VERSION "created by canmatrix"

NS_ :

BS_:

BU_:

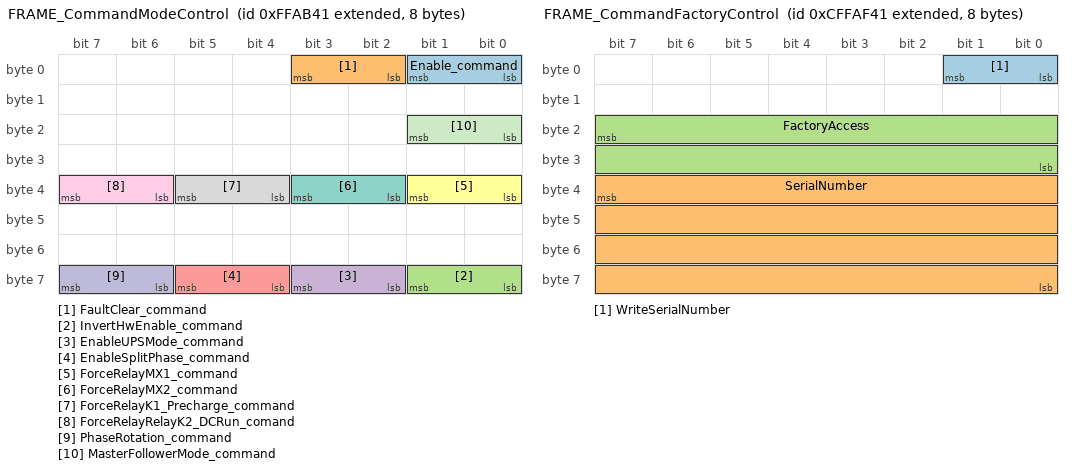
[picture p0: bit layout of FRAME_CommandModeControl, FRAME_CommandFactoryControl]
BO_ 2164239169 FRAME_CommandModeControl: 8 Vector__XXX
 SG_ Enable_command : 1|2@0- (1,0) [-2|1] "" Vector__XXX
 SG_ FaultClear_command : 3|2@0- (1,0) [-2|1] "" Vector__XXX
 SG_ InvertHwEnable_command : 57|2@0- (1,0) [-2|1] "" Vector__XXX
 SG_ EnableUPSMode_command : 59|2@0- (1,0) [-2|1] "" Vector__XXX
 SG_ EnableSplitPhase_command : 61|2@0- (1,0) [-2|1] "" Vector__XXX
 SG_ ForceRelayMX1_command : 33|2@0- (1,0) [-2|1] "" Vector__XXX
 SG_ ForceRelayMX2_command : 35|2@0- (1,0) [-2|1] "" Vector__XXX
 SG_ ForceRelayK1_Precharge_command : 37|2@0- (1,0) [-2|1] "" Vector__XXX
 SG_ ForceRelayRelayK2_DCRun_comand : 39|2@0- (1,0) [-2|1] "" Vector__XXX
 SG_ PhaseRotation_command : 63|2@0- (1,0) [-2|1] "" Vector__XXX
 SG_ MasterFollowerMode_command : 17|2@0- (1,0) [-2|1] "" Vector__XXX

BO_ 2365566017 FRAME_CommandPower: 8 Vector__XXX
 SG_ RealPower_command : 7|32@0- (1,0) [-2147483648|2147483647] "" Vector__XXX
 SG_ ReactivePower_command : 39|32@0- (1,0) [-2147483648|2147483647] "" Vector__XXX

BO_ 2365566529 FRAME_CommandVF: 8 Vector__XXX
 SG_ Voltage_command : 7|16@0- (0.1,0) [-3276.8|3276.7000000000003] "" Vector__XXX
 SG_ Frequency_command : 23|16@0- (0.1,0) [-3276.8|3276.7000000000003] "" Vector__XXX

BO_ 2365573878 FRAME_MasterMeasuredPower: 8 Vector__XXX
 SG_ RealPower_measured : 7|32@0- (1,0) [-2147483648|2147483647] "" Vector__XXX
 SG_ ReactivePower_measured : 39|32@0- (1,0) [-2147483648|2147483647] "" Vector__XXX

BO_ 2365566785 FRAME_CommandFactoryControl: 8 Vector__XXX
 SG_ WriteSerialNumber : 1|2@0- (1,0) [-2|1] "" Vector__XXX
 SG_ SerialNumber : 39|32@0- (1,0) [-2147483648|2147483647] "" Vector__XXX
 SG_ FactoryAccess : 23|16@0- (1,0) [-32768|32767] "" Vector__XXX

BO_ 2365565505 FRAME_CommandSetNVParam: 8 Vector__XXX
 SG_ CommandSetNVParam_MUX : 7|16@0- (1,0) [-32768|32767] "" Vector__XXX
 SG_ Dummy : 23|16@0- (1,0) [-32768|32767] "" Vector__XXX
 SG_ VUnder50pct : 23|16@0- (1,0) [-32768|32767] "" Vector__XXX
 SG_ V50to88pct : 39|16@0- (1,0) [-32768|32767] "" Vector__XXX
 SG_ V110to120pct : 55|16@0- (1,0) [-32768|32767] "" Vector__XXX
 SG_ VOver120 : 23|16@0- (1,0) [-32768|32767] "" Vector__XXX
 SG_ FreqHi0 : 23|16@0- (0.1,0) [-3276.8|3276.7000000000003] "" Vector__XXX
 SG_ FreqLo0 : 39|16@0- (0.1,0) [-3276.8|3276.7000000000003] "" Vector__XXX
 SG_ FreqVeryLo0 : 55|16@0- (0.1,0) [-3276.8|3276.7000000000003] "" Vector__XXX
 SG_ FreqVeryLo1 : 23|16@0- (0.1,0) [-3276.8|3276.7000000000003] "" Vector__XXX
 SG_ FreqLo1 : 39|16@0- (0.1,0) [-3276.8|3276.7000000000003] "" Vector__XXX
 SG_ FreqHi1 : 55|16@0- (0.1,0) [-3276.8|3276.7000000000003] "" Vector__XXX
 SG_ NodeID : 23|8@0- (1,0) [-128|127] "" Vector__XXX
 SG_ SA_Mask : 31|8@0- (1,0) [-128|127] "" Vector__XXX
 SG_ Baudrate : 39|4@0- (1,0) [-8|7] "" Vector__XXX
 SG_ ThermalOverload : 17|2@0- (1,0) [-2|1] "" Vector__XXX
 SG_ MX1Open : 23|16@0- (1,0) [-32768|32767] "" Vector__XXX
 SG_ MX1Close : 39|16@0- (1,0) [-32768|32767] "" Vector__XXX
 SG_ MX2Open : 55|16@0- (1,0) [-32768|32767] "" Vector__XXX
 SG_ MX2Close : 23|16@0- (1,0) [-32768|32767] "" Vector__XXX
 SG_ K1Open : 39|16@0- (1,0) [-32768|32767] "" Vector__XXX
 SG_ K1Close : 55|16@0- (1,0) [-32768|32767] "" Vector__XXX
 SG_ K2Open : 23|16@0- (1,0) [-32768|32767] "" Vector__XXX
 SG_ K2Close : 39|16@0- (1,0) [-32768|32767] "" Vector__XXX

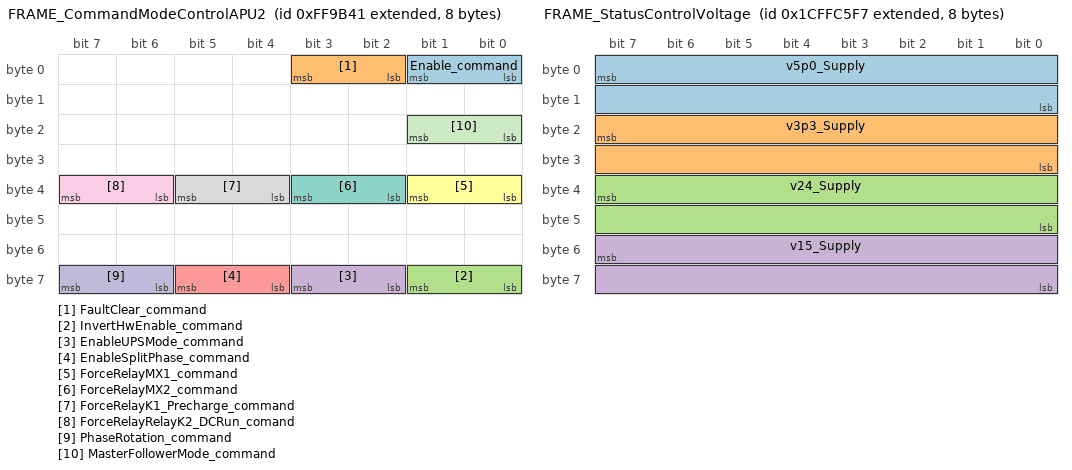
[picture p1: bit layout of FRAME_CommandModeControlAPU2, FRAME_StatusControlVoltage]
BO_ 2164235073 FRAME_CommandModeControlAPU2: 8 Vector__XXX
 SG_ Enable_command : 1|2@0- (1,0) [-2|1] "" Vector__XXX
 SG_ FaultClear_command : 3|2@0- (1,0) [-2|1] "" Vector__XXX
 SG_ InvertHwEnable_command : 57|2@0- (1,0) [-2|1] "" Vector__XXX
 SG_ EnableUPSMode_command : 59|2@0- (1,0) [-2|1] "" Vector__XXX
 SG_ EnableSplitPhase_command : 61|2@0- (1,0) [-2|1] "" Vector__XXX
 SG_ ForceRelayMX1_command : 33|2@0- (1,0) [-2|1] "" Vector__XXX
 SG_ ForceRelayMX2_command : 35|2@0- (1,0) [-2|1] "" Vector__XXX
 SG_ ForceRelayK1_Precharge_command : 37|2@0- (1,0) [-2|1] "" Vector__XXX
 SG_ ForceRelayRelayK2_DCRun_comand : 39|2@0- (1,0) [-2|1] "" Vector__XXX
 SG_ PhaseRotation_command : 63|2@0- (1,0) [-2|1] "" Vector__XXX
 SG_ MasterFollowerMode_command : 17|2@0- (1,0) [-2|1] "" Vector__XXX

BO_ 2365561921 FRAME_CommandPowerAPU2: 8 Vector__XXX
 SG_ RealPower_command : 7|32@0- (1,0) [-2147483648|2147483647] "" Vector__XXX
 SG_ ReactivePower_command : 39|32@0- (1,0) [-2147483648|2147483647] "" Vector__XXX

BO_ 2365562433 FRAME_CommandVFAPU2: 8 Vector__XXX
 SG_ Voltage_command : 7|16@0- (0.1,0) [-3276.8|3276.7000000000003] "" Vector__XXX
 SG_ Frequency_command : 23|16@0- (0.1,0) [-3276.8|3276.7000000000003] "" Vector__XXX

BO_ 2365573879 FRAME_MasterMeasuredPowerAPU2: 8 Vector__XXX
 SG_ RealPower_measured : 7|32@0- (1,0) [-2147483648|2147483647] "" Vector__XXX
 SG_ ReactivePower_measured : 39|32@0- (1,0) [-2147483648|2147483647] "" Vector__XXX

BO_ 2634001600 FRAME_justString: 8 Vector__XXX

BO_ 2634001344 FRAME_stringAndOther: 8 Vector__XXX
 SG_ RealPower_measured : 7|32@0- (1,0) [-2147483648|2147483647] "" Vector__XXX

BO_ 2365573879 FRAME_StatusMeasuredPower: 8 Vector__XXX
 SG_ RealPower_measured : 7|32@0- (1,0) [-2147483648|2147483647] "" Vector__XXX
 SG_ ReactivePower_measured : 39|32@0- (1,0) [-2147483648|2147483647] "" Vector__XXX

BO_ 2566898935 FRAME_StatusCommandedPower: 8 Vector__XXX
 SG_ RealPower_echo : 7|32@0- (1,0) [-2147483648|2147483647] "" Vector__XXX
 SG_ ReactivePower_echo : 39|32@0- (1,0) [-2147483648|2147483647] "" Vector__XXX

BO_ 2365572087 FRAME_StatusBits: 8 Vector__XXX
 SG_ State_status : 3|4@0- (1,0) [-8|7] "" Vector__XXX
 SG_ MX2Permissive_status : 19|2@0- (1,0) [-2|1] "" Vector__XXX
 SG_ PowerAvailAC_status : 11|2@0- (1,0) [-2|1] "" Vector__XXX
 SG_ PowerAvailDC_status : 13|2@0- (1,0) [-2|1] "" Vector__XXX
 SG_ PowerCircuitEnabled_status : 15|2@0- (1,0) [-2|1] "" Vector__XXX
 SG_ HardwareEnable_status : 9|2@0- (1,0) [-2|1] "" Vector__XXX
 SG_ Enable_echo : 5|2@0- (1,0) [-2|1] "" Vector__XXX
 SG_ FaultClr_echo : 7|2@0- (1,0) [-2|1] "" Vector__XXX
 SG_ MessageValidModeControl_status : 25|2@0- (1,0) [-2|1] "" Vector__XXX
 SG_ MX1Permissive_status : 17|2@0- (1,0) [-2|1] "" Vector__XXX
 SG_ K2DCRunPermissive_status : 23|2@0- (1,0) [-2|1] "" Vector__XXX
 SG_ K1PrechargePermissive_status : 21|2@0- (1,0) [-2|1] "" Vector__XXX
 SG_ MessageValidPowerCMD_status : 27|2@0- (1,0) [-2|1] "" Vector__XXX
 SG_ MessageValidVF_status : 29|2@0- (1,0) [-2|1] "" Vector__XXX
 SG_ CANbus_status : 31|2@0- (1,0) [-2|1] "" Vector__XXX
 SG_ EnableUPSMode_echo : 33|2@0- (1,0) [-2|1] "" Vector__XXX
 SG_ EnableSplitPhase_echo : 35|2@0- (1,0) [-2|1] "" Vector__XXX
 SG_ PhaseRotation_status : 37|2@0- (1,0) [-2|1] "" Vector__XXX
 SG_ LineVoltageDetected_status : 39|2@0- (1,0) [-2|1] "" Vector__XXX
 SG_ PhaseRotation_echo : 41|2@0- (1,0) [-2|1] "" Vector__XXX

BO_ 2634008055 FRAME_StatusControlVoltage: 8 Vector__XXX
 SG_ v5p0_Supply : 7|16@0- (0.01,0) [-327.68|327.67] "" Vector__XXX
 SG_ v3p3_Supply : 23|16@0- (0.01,0) [-327.68|327.67] "" Vector__XXX
 SG_ v24_Supply : 39|16@0- (0.01,0) [-327.68|327.67] "" Vector__XXX
 SG_ v15_Supply : 55|16@0- (0.01,0) [-327.68|327.67] "" Vector__XXX

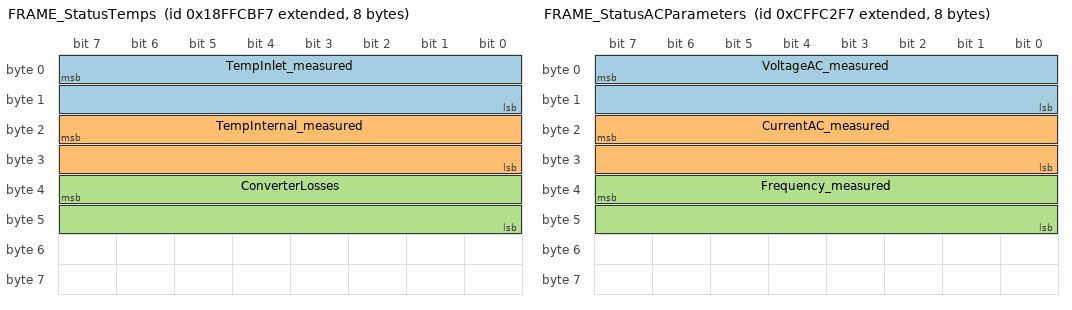
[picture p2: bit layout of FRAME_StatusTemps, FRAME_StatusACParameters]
BO_ 2566900727 FRAME_StatusTemps: 8 Vector__XXX
 SG_ TempInlet_measured : 7|16@0- (0.1,0) [-3276.8|3276.7000000000003] "" Vector__XXX
 SG_ TempInternal_measured : 23|16@0- (0.1,0) [-3276.8|3276.7000000000003] "" Vector__XXX
 SG_ ConverterLosses : 39|16@0- (1,0) [-32768|32767] "" Vector__XXX

BO_ 2365573367 FRAME_StatusFaults: 8 Vector__XXX
 SG_ BridgeAVoltageOk_status : 59|1@0- (1,0) [-1|0] "" Vector__XXX
 SG_ OvercurrentAC_status : 3|2@0- (1,0) [-2|1] "" Vector__XXX
 SG_ BridgeBVoltageOk_status : 43|1@0- (1,0) [-1|0] "" Vector__XXX
 SG_ OvervoltageDC_status : 9|2@0- (1,0) [-2|1] "" Vector__XXX
 SG_ OvertempPowerDevice_status : 15|2@0- (1,0) [-2|1] "" Vector__XXX
 SG_ OvertempInternal_status : 13|2@0- (1,0) [-2|1] "" Vector__XXX
 SG_ LossValidControlMessage_status : 23|4@0- (1,0) [-8|7] "" Vector__XXX
 SG_ UndervoltageDC_status : 11|2@0- (1,0) [-2|1] "" Vector__XXX
 SG_ ControlHardwareFail_status : 19|4@0- (1,0) [-8|7] "" Vector__XXX
 SG_ OvercurrentDC_status : 7|2@0- (1,0) [-2|1] "" Vector__XXX
 SG_ GeneralFault_status : 1|2@0- (1,0) [-2|1] "" Vector__XXX
 SG_ LossOfAC_status : 5|2@0- (1,0) [-2|1] "" Vector__XXX
 SG_ EStopShutdown_status : 25|2@0- (1,0) [-2|1] "" Vector__XXX
 SG_ BridgeAFault_status : 58|3@0- (1,0) [-4|3] "" Vector__XXX
 SG_ BridgeBFault_status : 42|3@0- (1,0) [-4|3] "" Vector__XXX
 SG_ IllegalTransition_status : 27|2@0- (1,0) [-2|1] "" Vector__XXX
 SG_ InvalidEEHeader_status : 29|2@0- (1,0) [-2|1] "" Vector__XXX
 SG_ InvalidEESection_status : 31|2@0- (1,0) [-2|1] "" Vector__XXX
 SG_ ThermalOverload : 33|2@0- (1,0) [-2|1] "" Vector__XXX

BO_ 2365571831 FRAME_StatusACParameters: 8 Vector__XXX
 SG_ VoltageAC_measured : 7|16@0- (0.1,0) [-3276.8|3276.7000000000003] "" Vector__XXX
 SG_ CurrentAC_measured : 23|16@0- (1,0) [-32768|32767] "" Vector__XXX
 SG_ Frequency_measured : 39|16@0- (0.1,0) [-3276.8|3276.7000000000003] "" Vector__XXX

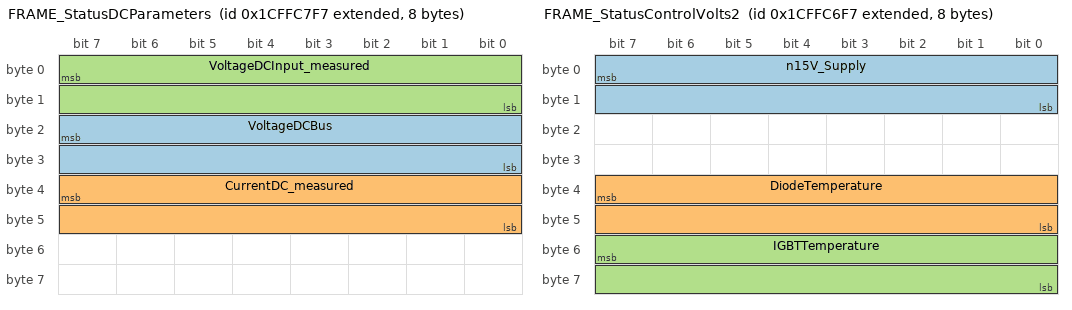
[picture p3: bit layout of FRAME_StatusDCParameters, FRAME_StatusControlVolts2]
BO_ 2634008567 FRAME_StatusDCParameters: 8 Vector__XXX
 SG_ VoltageDCBus : 23|16@0- (1,0) [-32768|32767] "" Vector__XXX
 SG_ CurrentDC_measured : 39|16@0- (1,0) [-32768|32767] "" Vector__XXX
 SG_ VoltageDCInput_measured : 7|16@0- (1,0) [-32768|32767] "" Vector__XXX

BO_ 2634008311 FRAME_StatusControlVolts2: 8 Vector__XXX
 SG_ n15V_Supply : 7|16@0- (0.01,0) [-327.68|327.67] "" Vector__XXX
 SG_ DiodeTemperature : 39|16@0- (1,0) [-32768|32767] "" Vector__XXX
 SG_ IGBTTemperature : 55|16@0- (1,0) [-32768|32767] "" Vector__XXX

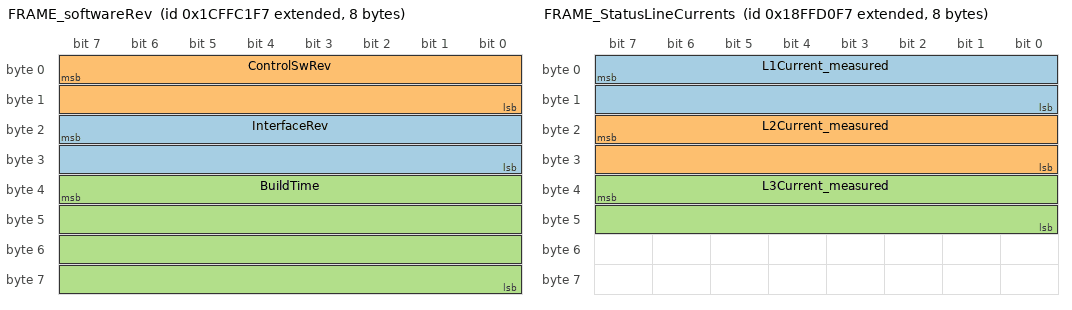
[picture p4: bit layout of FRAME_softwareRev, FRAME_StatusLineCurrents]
BO_ 2634007031 FRAME_softwareRev: 8 Vector__XXX
 SG_ InterfaceRev : 23|16@0- (0.01,0) [-327.68|327.67] "" Vector__XXX
 SG_ ControlSwRev : 7|16@0- (0.01,0) [-327.68|327.67] "" Vector__XXX
 SG_ BuildTime : 39|32@0- (1,0) [-2147483648|2147483647] "" Vector__XXX

BO_ 2566900215 FRAME_StatusCommandVF: 8 Vector__XXX
 SG_ Voltage_echo : 7|16@0- (0.1,0) [-3276.8|3276.7000000000003] "" Vector__XXX
 SG_ Frequency_echo : 23|16@0- (0.1,0) [-3276.8|3276.7000000000003] "" Vector__XXX

BO_ 2634009847 FRAME_serialNumber: 8 Vector__XXX
 SG_ SerialNumber : 7|32@0- (1,0) [-2147483648|2147483647] "" Vector__XXX

BO_ 2634010103 FRAME_softwareRevHash: 8 Vector__XXX
 SG_ Hash : 7|28@0- (1,0) [-134217728|134217727] "" Vector__XXX

BO_ 2634000887 FRAME_StatusNVParam: 8 Vector__XXX
 SG_ StatusNVParam_MUX : 7|16@0- (1,0) [-32768|32767] "" Vector__XXX
 SG_ Dummy : 23|16@0- (1,0) [-32768|32767] "" Vector__XXX
 SG_ VUnder50pct : 23|16@0- (1,0) [-32768|32767] "" Vector__XXX
 SG_ V50to88pct : 39|16@0- (1,0) [-32768|32767] "" Vector__XXX
 SG_ V110to120pct : 55|16@0- (1,0) [-32768|32767] "" Vector__XXX
 SG_ VOver120 : 23|16@0- (1,0) [-32768|32767] "" Vector__XXX
 SG_ FreqHi0 : 23|16@0- (0.1,0) [-3276.8|3276.7000000000003] "" Vector__XXX
 SG_ FreqLo0 : 39|16@0- (0.1,0) [-3276.8|3276.7000000000003] "" Vector__XXX
 SG_ FreqVeryLo0 : 55|16@0- (0.1,0) [-3276.8|3276.7000000000003] "" Vector__XXX
 SG_ FreqVeryLo1 : 23|16@0- (0.1,0) [-3276.8|3276.7000000000003] "" Vector__XXX
 SG_ FreqLo1 : 39|16@0- (0.1,0) [-3276.8|3276.7000000000003] "" Vector__XXX
 SG_ FreqHi1 : 55|16@0- (0.1,0) [-3276.8|3276.7000000000003] "" Vector__XXX
 SG_ StatusNodeID : 23|8@0- (1,0) [-128|127] "" Vector__XXX
 SG_ StatusSA_Mask : 31|8@0- (1,0) [-128|127] "" Vector__XXX
 SG_ StatusBaudrate : 39|4@0- (1,0) [-8|7] "" Vector__XXX
 SG_ StatusThermalOverload : 17|2@0- (1,0) [-2|1] "" Vector__XXX
 SG_ StatusMX1Open : 23|16@0- (1,0) [-32768|32767] "" Vector__XXX
 SG_ StatusMX1Close : 39|16@0- (1,0) [-32768|32767] "" Vector__XXX
 SG_ StatusMX2Open : 55|16@0- (1,0) [-32768|32767] "" Vector__XXX
 SG_ StatusMX2Close : 23|16@0- (1,0) [-32768|32767] "" Vector__XXX
 SG_ StatusK1Open : 39|16@0- (1,0) [-32768|32767] "" Vector__XXX
 SG_ StatusK1Close : 55|16@0- (1,0) [-32768|32767] "" Vector__XXX
 SG_ StatusK2Open : 23|16@0- (1,0) [-32768|32767] "" Vector__XXX
 SG_ StatusK2Close : 39|16@0- (1,0) [-32768|32767] "" Vector__XXX

BO_ 2566902007 FRAME_StatusLineCurrents: 8 Vector__XXX
 SG_ L1Current_measured : 7|16@0- (1,0) [-32768|32767] "" Vector__XXX
 SG_ L2Current_measured : 23|16@0- (1,0) [-32768|32767] "" Vector__XXX
 SG_ L3Current_measured : 39|16@0- (1,0) [-32768|32767] "" Vector__XXX

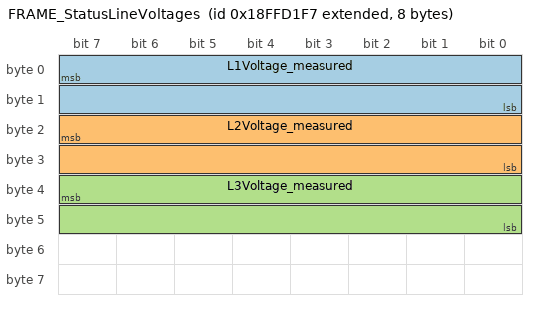
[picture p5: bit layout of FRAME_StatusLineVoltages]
BO_ 2566902263 FRAME_StatusLineVoltages: 8 Vector__XXX
 SG_ L1Voltage_measured : 7|16@0- (0.1,0) [-3276.8|3276.7000000000003] "" Vector__XXX
 SG_ L2Voltage_measured : 23|16@0- (0.1,0) [-3276.8|3276.7000000000003] "" Vector__XXX
 SG_ L3Voltage_measured : 39|16@0- (0.1,0) [-3276.8|3276.7000000000003] "" Vector__XXX

CM_ BO_ 2164239169  "Operational commands are received by the module via control bits within this message.";
CM_ BO_ 2365566017  "Sets the desired real (P) and reactive (Q) power levels for the module to follow while in the GRID FOLLOWING mode.";
CM_ BO_ 2365566529  "Sets the desired voltage and frequency for the module to produce while in the GRID FORMING mode.  In addition, while in the READY and GRID FOLLOWING modes, this message is used to set the nominal voltage levels for detection of acceptable AC line voltage.";
CM_ BO_ 2365573878  "Returns the actual measured power.";
CM_ BO_ 2365565505  "Provides access to configure non-volatile parameters.  Note that these parameters can only be set when the inverter's power stage is disabled (PowerCircuitEnabled_status in StatusBits message is 'Disabled.')";
CM_ BO_ 2164235073  "Operational commands are received by the module via control bits within this message.";
CM_ BO_ 2365561921  "Sets the desired real (P) and reactive (Q) power levels for the module to follow while in the GRID FOLLOWING mode.";
CM_ BO_ 2365562433  "Sets the desired voltage and frequency for the module to produce while in the GRID FORMING mode.  In addition, while in the READY and GRID FOLLOWING modes, this message is used to set the nominal voltage levels for detection of acceptable AC line voltage.";
CM_ BO_ 2365573879  "Returns the actual measured power.";
CM_ BO_ 2365573879  "Returns the actual measured power.";
CM_ BO_ 2566898935  "Echoes the commanded power (P&Q) as received in CommandPQ.";
CM_ BO_ 2365572087  "Bits representing the status of the power module.";
CM_ BO_ 2634008055  "Lists present voltage of each power supply on the control board (24V, 15V, 5V, and 3.3V.)";
CM_ BO_ 2566900727  "Returns the inlet water temperature to the module as well as module internal ambient temperature.";
CM_ BO_ 2365573367  "Fault bits.";
CM_ BO_ 2365571831  "RMS AC Voltage, current, and frequency measured by line A, B and C feedbacks.";
CM_ BO_ 2634008567  "Measured (boosted) DC Bus voltage, DC Current, and estimated DC Input voltage.";
CM_ BO_ 2634008311  "Present voltage of the -15V power supply on the control board.";
CM_ BO_ 2634007031  "Software revision.";
CM_ BO_ 2566900215  "Echoes the voltage and frequency commands from commandVF.";
CM_ BO_ 2634009847  "Serial number of the power module.";
CM_ BO_ 2634010103  "Unique software revision identification hashcode.";
CM_ BO_ 2634000887  "Echos back parameter values.";
CM_ BO_ 2566902007  "Measured RMS line currents.";
CM_ BO_ 2566902263  "Measured RMS line voltages.";

CM_ SG_ 2164239169 Enable_command "Run command.  When set to a value of 'Enable', causes transition to grid forming or grid following mode depending on whether AC power is detected.  Must be set to 'Disable' to leave POR or FAULTED state.";
CM_ SG_ 2164239169 FaultClear_command "Clears the latched fault message.";
CM_ SG_ 2164239169 InvertHwEnable_command "Inverts the logic of the Hardware Enable input.";
CM_ SG_ 2164239169 EnableUPSMode_command "Enables uninterruptible operation when transitioning from GRID FOLLOWING to GRID FORMING operation.  If operating in GRID FOLLOWING mode, and AC grid voltage is interrupted, the module will transition to GRID FORMING mode, with no interruption in power.";
CM_ SG_ 2164239169 EnableSplitPhase_command "Dictates to the module whether it is connected to a three-phase (four wire) or split phase (L1, L2 and N) electrical system.";
CM_ SG_ 2164239169 ForceRelayMX1_command "If set to 'Force On,' will force the relay closed, overriding firmware state machine commands.  Meant for diagnostic purposes only.";
CM_ SG_ 2164239169 ForceRelayMX2_command "If set to 'Force On,' will force the relay closed, overriding firmware state machine commands.  Meant for diagnostic purposes only.";
CM_ SG_ 2164239169 ForceRelayK1_Precharge_command "If set to 'Force On,' will force the relay closed, overriding firmware state machine commands.  Meant for diagnostic purposes only.";
CM_ SG_ 2164239169 ForceRelayRelayK2_DCRun_comand "If set to 'Force On,' will force the relay closed, overriding firmware state machine commands.  Meant for diagnostic purposes only.";
CM_ SG_ 2164239169 PhaseRotation_command "Specifies phase rotation direction.  Only active while transitioning from READY to GRID_FORMING.";
CM_ SG_ 2164239169 MasterFollowerMode_command "Specifies what power command the inverter will follow in GRID FOLLOWING mode.  When configured as Master, CommandPower will be used as the power command.  When configured as Slave, the values in StatusMeasuredPower of the master inverter will be used.";
CM_ SG_ 2365566017 RealPower_command "Commanded real power (W) while in grid following mode - positive real power is defined as power being put into the ac network.";
CM_ SG_ 2365566017 ReactivePower_command "Commanded reactive power (VA) while in grid following mode - positive reactive power is defined as the converter having a leading power factor.";
CM_ SG_ 2365566529 Voltage_command "Desired output voltage while in grid forming mode.";
CM_ SG_ 2365566529 Frequency_command "Desired output frequency while in grid forming mode.";
CM_ SG_ 2365573878 RealPower_measured "Measured real power of master unit.";
CM_ SG_ 2365573878 ReactivePower_measured "Measured reactive power of master unit.";
CM_ SG_ 2365565505 VUnder50pct "Determines the fault trip time when Line-to-line rms voltage for a phase remains under 50 percent of the nominal value specified in the CommandVF message while the inverter is running in GRID FOLLOWING mode.";
CM_ SG_ 2365565505 V50to88pct "Determines the fault trip time when Line-to-line rms voltage for a phase remains between 50 and 88 percent of the nominal value specified in the CommandVF message while the inverter is running in GRID FOLLOWING mode.";
CM_ SG_ 2365565505 V110to120pct "Determines the fault trip time when Line-to-line rms voltage for a phase remains between 110 and 120 percent of the nominal value specified in the CommandVF message while the inverter is running in GRID FOLLOWING mode.";
CM_ SG_ 2365565505 VOver120 "Determines the fault trip time when Line-to-line rms voltage for a phase remains Over 120 percent of the nominal value specified in the CommandVF message while the inverter is running in GRID FOLLOWING mode.";
CM_ SG_ 2365565505 FreqHi0 "Determines the upper bound, above which the frequency monitor will trip if the line frequency remains for the time specified in FreqHi of the LFM_ClearingTimes Mux.";
CM_ SG_ 2365565505 FreqLo0 "Determines the upper bound, in which the frequency monitor will trip if the line frequency remains below this bound but above the value of FreqVeryLo for the time specified in FreqLo of the LFM_ClearingTimes Mux.";
CM_ SG_ 2365565505 FreqVeryLo0 "Determines the upper bound, in which the frequency monitor will trip if the line frequency remains below this bound but above the value of FreqVeryLo for the time specified in FreqLo of the LFM_ClearingTimes Mux.";
CM_ SG_ 2365565505 FreqVeryLo1 "Determines the upper bound, in which the frequency monitor will trip if the line frequency remains below this bound but above the value of FreqVeryLo for the time specified in FreqLo of the LFM_ClearingTimes Mux.";
CM_ SG_ 2365565505 FreqLo1 "Determines the upper bound, in which the frequency monitor will trip if the line frequency remains below this bound but above the value of FreqVeryLo for the time specified in FreqLo of the LFM_ClearingTimes Mux.";
CM_ SG_ 2365565505 FreqHi1 "Determines the upper bound, above which the frequency monitor will trip if the line frequency remains for the time specified in FreqHi of the LFM_ClearingTimes Mux.";
CM_ SG_ 2365565505 NodeID "J1939 Source Address node for the module.";
CM_ SG_ 2365565505 SA_Mask "Not presently used.";
CM_ SG_ 2365565505 Baudrate "CAN baudrate";
CM_ SG_ 2365565505 ThermalOverload "Configures action to take when thermal overload input is active.";
CM_ SG_ 2365565505 MX1Open "Maximum time required for the MX1 contactor to open.";
CM_ SG_ 2365565505 MX1Close "Maximum time required for the MX1 contactor to close.";
CM_ SG_ 2365565505 MX2Open "Maximum time required for the MX2 contactor to open.";
CM_ SG_ 2365565505 MX2Close "Maximum time required for the MX2 contactor to open.";
CM_ SG_ 2365565505 K1Open "Maximum time required for the K1 contactor to open.";
CM_ SG_ 2365565505 K1Close "Maximum time required for the K1 contactor to close.";
CM_ SG_ 2365565505 K2Open "Maximum time required for the K2 contactor to open.";
CM_ SG_ 2365565505 K2Close "Maximum time required for the K2 contactor to close.";
CM_ SG_ 2164235073 Enable_command "Run command.  When set to a value of 'Enable', causes transition to grid forming or grid following mode depending on whether AC power is detected.  Must be set to 'Disable' to leave POR or FAULTED state.";
CM_ SG_ 2164235073 FaultClear_command "Clears the latched fault message.";
CM_ SG_ 2164235073 InvertHwEnable_command "Inverts the logic of the Hardware Enable input.";
CM_ SG_ 2164235073 EnableUPSMode_command "Enables uninterruptible operation when transitioning from GRID FOLLOWING to GRID FORMING operation.  If operating in GRID FOLLOWING mode, and AC grid voltage is interrupted, the module will transition to GRID FORMING mode, with no interruption in power.";
CM_ SG_ 2164235073 EnableSplitPhase_command "Dictates to the module whether it is connected to a three-phase (four wire) or split phase (L1, L2 and N) electrical system.";
CM_ SG_ 2164235073 ForceRelayMX1_command "If set to 'Force On,' will force the relay closed, overriding firmware state machine commands.  Meant for diagnostic purposes only.";
CM_ SG_ 2164235073 ForceRelayMX2_command "If set to 'Force On,' will force the relay closed, overriding firmware state machine commands.  Meant for diagnostic purposes only.";
CM_ SG_ 2164235073 ForceRelayK1_Precharge_command "If set to 'Force On,' will force the relay closed, overriding firmware state machine commands.  Meant for diagnostic purposes only.";
CM_ SG_ 2164235073 ForceRelayRelayK2_DCRun_comand "If set to 'Force On,' will force the relay closed, overriding firmware state machine commands.  Meant for diagnostic purposes only.";
CM_ SG_ 2164235073 PhaseRotation_command "Specifies phase rotation direction.  Only active while transitioning from READY to GRID_FORMING.";
CM_ SG_ 2164235073 MasterFollowerMode_command "Specifies what power command the inverter will follow in GRID FOLLOWING mode.  When configured as Master, CommandPower will be used as the power command.  When configured as Slave, the values in StatusMeasuredPower of the master inverter will be used.";
CM_ SG_ 2365561921 RealPower_command "Commanded real power (W) while in grid following mode - positive real power is defined as power being put into the ac network.";
CM_ SG_ 2365561921 ReactivePower_command "Commanded reactive power (VA) while in grid following mode - positive reactive power is defined as the converter having a leading power factor.";
CM_ SG_ 2365562433 Voltage_command "Desired output voltage while in grid forming mode.";
CM_ SG_ 2365562433 Frequency_command "Desired output frequency while in grid forming mode.";
CM_ SG_ 2365573879 RealPower_measured "Measured real power of master unit.";
CM_ SG_ 2365573879 ReactivePower_measured "Measured reactive power of master unit.";
CM_ SG_ 2634001344 RealPower_measured "Measured real power of master unit.";
CM_ SG_ 2365573879 RealPower_measured "Measured real power of master unit.";
CM_ SG_ 2365573879 ReactivePower_measured "Measured reactive power of master unit.";
CM_ SG_ 2566898935 RealPower_echo "Echoed real power command.";
CM_ SG_ 2566898935 ReactivePower_echo "Echoed reactive power command.";
CM_ SG_ 2365572087 State_status "Active control mode.";
CM_ SG_ 2365572087 MX2Permissive_status "MX2 relay status";
CM_ SG_ 2365572087 PowerAvailAC_status "Indicates that AC power is connected and that voltage and frequency are within nominal ranges.";
CM_ SG_ 2365572087 PowerAvailDC_status "Indicates that DC bus voltage is within operating range.";
CM_ SG_ 2365572087 PowerCircuitEnabled_status "Indicates whether the switching devices are active.";
CM_ SG_ 2365572087 HardwareEnable_status "Status of the hardware enable.";
CM_ SG_ 2365572087 Enable_echo "Echos the state of the Enable command withing the CommandModeControl message.";
CM_ SG_ 2365572087 FaultClr_echo "Echos the state of the FaultClear command withing the CommandModeControl message.";
CM_ SG_ 2365572087 MessageValidModeControl_status "Indicates the validity of the CommandModeControl message.  Message must be received at least once per second and parameter data within range to be considered valid.";
CM_ SG_ 2365572087 MX1Permissive_status "MX1 relay status";
CM_ SG_ 2365572087 K2DCRunPermissive_status "K2 DC Run relay status.";
CM_ SG_ 2365572087 K1PrechargePermissive_status "K1 precharge relay status.";
CM_ SG_ 2365572087 MessageValidPowerCMD_status "Indicates the validity of the CommandPQ message.  Message must be received at least once per second and parameter data within range to be considered valid.";
CM_ SG_ 2365572087 MessageValidVF_status "Indicates the validity of the CommandVF message.  Message must be received at least once per second and parameter data within range to be considered valid.";
CM_ SG_ 2365572087 CANbus_status "Operational status of the CAN bus driver.";
CM_ SG_ 2365572087 EnableUPSMode_echo "Echos the state of the EnableUPSMode command withing the CommandModeControl message.";
CM_ SG_ 2365572087 EnableSplitPhase_echo "Echos the state of the EnableSplitPhase command withing the CommandModeControl message.";
CM_ SG_ 2365572087 PhaseRotation_status "Phase rotation order.  When L1 phase angle leads L2 phase angle, rotation is considered positive.";
CM_ SG_ 2365572087 LineVoltageDetected_status "Flag indicating if voltage is detected on L1, L2 or L3.";
CM_ SG_ 2365572087 PhaseRotation_echo "Echos the state of PhaseRotation_command withing the CommandModeControl message.";
CM_ SG_ 2634008055 v5p0_Supply "Present voltage of the control board 5V power suppy.";
CM_ SG_ 2634008055 v3p3_Supply "Present voltage of the control board 3.3V power supply.";
CM_ SG_ 2634008055 v24_Supply "Present voltage of the control board 24V power supply.";
CM_ SG_ 2634008055 v15_Supply "Present voltage of the control board 15V power supply.";
CM_ SG_ 2566900727 TempInlet_measured "Coolant inlet temperature";
CM_ SG_ 2566900727 TempInternal_measured "Internal ambient temperature";
CM_ SG_ 2566900727 ConverterLosses "Power converter thermal loss";
CM_ SG_ 2365573367 BridgeAVoltageOk_status "Indicates whether a hardware trip has been activated.";
CM_ SG_ 2365573367 OvercurrentAC_status "Set immediately upon the software detection of AC current exceeding the threshold value.";
CM_ SG_ 2365573367 BridgeBVoltageOk_status "Indicates whether a hardware trip has been activated.";
CM_ SG_ 2365573367 OvervoltageDC_status "Set immediately upon the software detection of DC voltage exceeding the threshold value.";
CM_ SG_ 2365573367 OvertempPowerDevice_status "Set immediately upon the software detection of an IGBT temperature exceeding the threshold value.";
CM_ SG_ 2365573367 OvertempInternal_status "Set immediately upon the software detection of an internal inverter temperature exceeding the threshold value.";
CM_ SG_ 2365573367 LossValidControlMessage_status "Set whenever a control message required for operation contains out of range data or has not been received within the required timeout period.";
CM_ SG_ 2365573367 UndervoltageDC_status "Indicates loss of DC source voltage.";
CM_ SG_ 2365573367 ControlHardwareFail_status "Set upon the failure of control hardware to return expected response.";
CM_ SG_ 2365573367 OvercurrentDC_status "Set immediately upon the software detection of DC current exceeding the threshold value.";
CM_ SG_ 2365573367 GeneralFault_status "Will be set any time a fault shutdown has occurred.  It is always accompanied by an additional fault descriptor.";
CM_ SG_ 2365573367 LossOfAC_status "In grid following mode, this fault will be triggered if AC voltage or frequency goes outside of nominal bounds and EnableUPSMode is not set in the CommandModeControl message.";
CM_ SG_ 2365573367 EStopShutdown_status "Set when an enable request has been sent whithout the WakeUpSignal flag (hardware enable) in the StatusBits message being active.";
CM_ SG_ 2365573367 BridgeAFault_status "Each bridge has hardware protection features as a backup to software protection.  This bitfield indicates which, if any of these protection trips is active.";
CM_ SG_ 2365573367 BridgeBFault_status "Each bridge has hardware protection features as a backup to software protection.  This bitfield indicates which, if any of these protection trips is active.";
CM_ SG_ 2365573367 IllegalTransition_status "Indicates that an illegal state transition was requested.  For example, this fault will occur if Enable is commanded and line voltage is detected but AC power is not available.";
CM_ SG_ 2365573367 InvalidEEHeader_status "Indicates that reading of non-volatile parameters at power-up failed.";
CM_ SG_ 2365573367 InvalidEESection_status "Indicates that reading or writing of an non-volatile parameter section failed.";
CM_ SG_ 2365573367 ThermalOverload "Configures action to take when thermal overload input is active.";
CM_ SG_ 2365571831 VoltageAC_measured "Measured RMS AC voltage.";
CM_ SG_ 2365571831 CurrentAC_measured "Measured RMS AC current.";
CM_ SG_ 2365571831 Frequency_measured "Measured frequency.";
CM_ SG_ 2634008567 VoltageDCBus "Measured DC bus voltage.";
CM_ SG_ 2634008567 CurrentDC_measured "Measured DC current.";
CM_ SG_ 2634008567 VoltageDCInput_measured "Estimated DC input voltage.";
CM_ SG_ 2634008311 n15V_Supply "Present voltage of the control board -15V power supply.";
CM_ SG_ 2634008311 DiodeTemperature "Hottest diode";
CM_ SG_ 2634008311 IGBTTemperature "Hottest IGBT";
CM_ SG_ 2634007031 InterfaceRev "Software revision of the CAN communication interface.";
CM_ SG_ 2634007031 ControlSwRev "Software revision of the control firmware.";
CM_ SG_ 2634007031 BuildTime "Build timestamp.";
CM_ SG_ 2566900215 Voltage_echo "Echoed voltage command";
CM_ SG_ 2566900215 Frequency_echo "Echoed frequency command.";
CM_ SG_ 2634010103 Hash "Unique revision identification hashcode.";
CM_ SG_ 2634000887 VUnder50pct "Determines the fault trip time when Line-to-line rms voltage for a phase remains under 50 percent of the nominal value specified in the CommandVF message while the inverter is running in GRID FOLLOWING mode.";
CM_ SG_ 2634000887 V50to88pct "Determines the fault trip time when Line-to-line rms voltage for a phase remains between 50 and 88 percent of the nominal value specified in the CommandVF message while the inverter is running in GRID FOLLOWING mode.";
CM_ SG_ 2634000887 V110to120pct "Determines the fault trip time when Line-to-line rms voltage for a phase remains between 110 and 120 percent of the nominal value specified in the CommandVF message while the inverter is running in GRID FOLLOWING mode.";
CM_ SG_ 2634000887 VOver120 "Determines the fault trip time when Line-to-line rms voltage for a phase remains Over 120 percent of the nominal value specified in the CommandVF message while the inverter is running in GRID FOLLOWING mode.";
CM_ SG_ 2634000887 FreqHi0 "Determines the upper bound, above which the frequency monitor will trip if the line frequency remains for the time specified in FreqHi of the LFM_ClearingTimes Mux.";
CM_ SG_ 2634000887 FreqLo0 "Determines the upper bound, in which the frequency monitor will trip if the line frequency remains below this bound but above the value of FreqVeryLo for the time specified in FreqLo of the LFM_ClearingTimes Mux.";
CM_ SG_ 2634000887 FreqVeryLo0 "Determines the upper bound, in which the frequency monitor will trip if the line frequency remains below this bound but above the value of FreqVeryLo for the time specified in FreqLo of the LFM_ClearingTimes Mux.";
CM_ SG_ 2634000887 FreqVeryLo1 "Determines the upper bound, in which the frequency monitor will trip if the line frequency remains below this bound but above the value of FreqVeryLo for the time specified in FreqLo of the LFM_ClearingTimes Mux.";
CM_ SG_ 2634000887 FreqLo1 "Determines the upper bound, in which the frequency monitor will trip if the line frequency remains below this bound but above the value of FreqVeryLo for the time specified in FreqLo of the LFM_ClearingTimes Mux.";
CM_ SG_ 2634000887 FreqHi1 "Determines the upper bound, above which the frequency monitor will trip if the line frequency remains for the time specified in FreqHi of the LFM_ClearingTimes Mux.";
CM_ SG_ 2634000887 StatusNodeID "J1939 Source Address node for the module";
CM_ SG_ 2634000887 StatusSA_Mask "Mask used to configure from which master source addresses to accept commands.";
CM_ SG_ 2634000887 StatusThermalOverload "Configured action to take when thermal overload input is active.";
CM_ SG_ 2634000887 StatusMX1Open "Maximum time required for the MX1 contactor to open.";
CM_ SG_ 2634000887 StatusMX1Close "Maximum time required for the MX1 contactor to close.";
CM_ SG_ 2634000887 StatusMX2Open "Maximum time required for the MX2 contactor to open.";
CM_ SG_ 2634000887 StatusMX2Close "Maximum time required for the MX2 contactor to open.";
CM_ SG_ 2634000887 StatusK1Open "Maximum time required for the K1 contactor to open.";
CM_ SG_ 2634000887 StatusK1Close "Maximum time required for the K1 contactor to close.";
CM_ SG_ 2634000887 StatusK2Open "Maximum time required for the K2 contactor to open.";
CM_ SG_ 2634000887 StatusK2Close "Maximum time required for the K2 contactor to close.";
CM_ SG_ 2566902007 L1Current_measured "Measured L1 RMS line current.";
CM_ SG_ 2566902007 L2Current_measured "Measured L2 RMS line current.";
CM_ SG_ 2566902007 L3Current_measured "Measured L3 RMS line current.";
CM_ SG_ 2566902263 L1Voltage_measured "Measured L1 RMS line-neutral voltage";
CM_ SG_ 2566902263 L2Voltage_measured "Measured L2 RMS line-neutral voltage";
CM_ SG_ 2566902263 L3Voltage_measured "Measured L3 RMS line-neutral voltage";

BA_DEF_ BO_ "GenMsgSendType" ENUM  "cyclicX","spontanX","cyclicIfActiveX","spontanWithDelay","cyclicAndSpontanX","cyclicAndSpontanWithDelay","spontanWithRepitition","cyclicIfActiveAndSpontanWD","cyclicIfActiveFast","cyclicWithRepeatOnDemand","none";
BA_DEF_ BO_ "GenMsgStartValue" STRING;

BA_ "GenMsgSendType" BO_ 2164239169 1;
BA_ "GenMsgStartValue" BO_ 2164239169 "00000000";
BA_ "GenMsgSendType" BO_ 2365566017 1;
BA_ "GenMsgStartValue" BO_ 2365566017 "00000000";
BA_ "GenMsgSendType" BO_ 2365566529 1;
BA_ "GenMsgStartValue" BO_ 2365566529 "00000000";
BA_ "GenMsgSendType" BO_ 2365573878 1;
BA_ "GenMsgStartValue" BO_ 2365573878 "00000000";
BA_ "GenMsgSendType" BO_ 2365566785 1;
BA_ "GenMsgStartValue" BO_ 2365566785 "00000000";
BA_ "GenMsgSendType" BO_ 2365565505 1;
BA_ "GenMsgStartValue" BO_ 2365565505 "00000000";
BA_ "GenMsgSendType" BO_ 2164235073 1;
BA_ "GenMsgStartValue" BO_ 2164235073 "00000000";
BA_ "GenMsgSendType" BO_ 2365561921 1;
BA_ "GenMsgStartValue" BO_ 2365561921 "00000000";
BA_ "GenMsgSendType" BO_ 2365562433 1;
BA_ "GenMsgStartValue" BO_ 2365562433 "00000000";
BA_ "GenMsgSendType" BO_ 2365573879 1;
BA_ "GenMsgStartValue" BO_ 2365573879 "00000000";
BA_ "GenMsgSendType" BO_ 2634001600 1;
BA_ "GenMsgStartValue" BO_ 2634001600 "00000000";
BA_ "GenMsgSendType" BO_ 2634001344 1;
BA_ "GenMsgStartValue" BO_ 2634001344 "00000000";
BA_ "GenMsgSendType" BO_ 2365573879 1;
BA_ "GenMsgStartValue" BO_ 2365573879 "00000000";
BA_ "GenMsgSendType" BO_ 2566898935 1;
BA_ "GenMsgStartValue" BO_ 2566898935 "00000000";
BA_ "GenMsgSendType" BO_ 2365572087 1;
BA_ "GenMsgStartValue" BO_ 2365572087 "00000000";
BA_ "GenMsgSendType" BO_ 2634008055 1;
BA_ "GenMsgStartValue" BO_ 2634008055 "00000000";
BA_ "GenMsgSendType" BO_ 2566900727 1;
BA_ "GenMsgStartValue" BO_ 2566900727 "00000000";
BA_ "GenMsgSendType" BO_ 2365573367 1;
BA_ "GenMsgStartValue" BO_ 2365573367 "00000000";
BA_ "GenMsgSendType" BO_ 2365571831 1;
BA_ "GenMsgStartValue" BO_ 2365571831 "00000000";
BA_ "GenMsgSendType" BO_ 2634008567 1;
BA_ "GenMsgStartValue" BO_ 2634008567 "00000000";
BA_ "GenMsgSendType" BO_ 2634008311 1;
BA_ "GenMsgStartValue" BO_ 2634008311 "00000000";
BA_ "GenMsgSendType" BO_ 2634007031 1;
BA_ "GenMsgStartValue" BO_ 2634007031 "00000000";
BA_ "GenMsgSendType" BO_ 2566900215 1;
BA_ "GenMsgStartValue" BO_ 2566900215 "00000000";
BA_ "GenMsgSendType" BO_ 2634009847 1;
BA_ "GenMsgStartValue" BO_ 2634009847 "00000000";
BA_ "GenMsgSendType" BO_ 2634010103 1;
BA_ "GenMsgStartValue" BO_ 2634010103 "00000000";
BA_ "GenMsgSendType" BO_ 2634000887 1;
BA_ "GenMsgStartValue" BO_ 2634000887 "00000000";
BA_ "GenMsgSendType" BO_ 2566902007 1;
BA_ "GenMsgStartValue" BO_ 2566902007 "00000000";
BA_ "GenMsgSendType" BO_ 2566902263 1;
BA_ "GenMsgStartValue" BO_ 2566902263 "00000000";

VAL_ 2164239169 Enable_command 0 "Disable" 1 "Enable" 2 "Error" 3 "N/A";
VAL_ 2164239169 FaultClear_command 0 "Normal" 1 "Clear Faults" 2 "Error" 3 "N/A";
VAL_ 2164239169 InvertHwEnable_command 0 "No invert" 1 "Invert" 2 "Error" 3 "N/A";
VAL_ 2164239169 EnableUPSMode_command 0 "Disable" 1 "Enable" 2 "Error" 3 "N/A";
VAL_ 2164239169 EnableSplitPhase_command 0 "Normal - Three Phase Mode" 1 "Enable Split Phase Mode" 2 "Error" 3 "N/A";
VAL_ 2164239169 ForceRelayMX1_command 0 "Normal" 1 "Force On" 2 "Error" 3 "N/A";
VAL_ 2164239169 ForceRelayMX2_command 0 "Normal" 1 "Force On" 2 "Error" 3 "N/A";
VAL_ 2164239169 ForceRelayK1_Precharge_command 0 "Normal" 1 "Force On" 2 "Error" 3 "N/A";
VAL_ 2164239169 ForceRelayRelayK2_DCRun_comand 0 "Normal" 1 "Force On" 2 "Error" 3 "N/A";
VAL_ 2164239169 PhaseRotation_command 0 "Negative" 1 "Positive" 2 "Error" 3 "N/A";
VAL_ 2164239169 MasterFollowerMode_command 0 "Master" 1 "Follower" 2 "Error" 3 "N/A";
VAL_ 2365566785 WriteSerialNumber 0 "Disable" 1 "Enable" 2 "Error" 3 "N/A";
VAL_ 2365565505 CommandSetNVParam_MUX 0 "Param0" 1 "LVM_ClearingTimes1" 2 "LVM_ClearingTimes2" 3 "LFM_Limits" 4 "LFM_ClearingTimes" 5 "J1939_Interface" 6 "Fault_Config" 7 "ContactorDelays1" 8 "ContactorDelays2" 10 "ContactorDelays3";
VAL_ 2365565505 Baudrate 0 "125K" 1 "250K" 2 "500K" 3 "1M";
VAL_ 2365565505 ThermalOverload 0 "Warning" 1 "Fault" 2 "Error" 3 "N/A";
VAL_ 2164235073 Enable_command 0 "Disable" 1 "Enable" 2 "Error" 3 "N/A";
VAL_ 2164235073 FaultClear_command 0 "Normal" 1 "Clear Faults" 2 "Error" 3 "N/A";
VAL_ 2164235073 InvertHwEnable_command 0 "No invert" 1 "Invert" 2 "Error" 3 "N/A";
VAL_ 2164235073 EnableUPSMode_command 0 "Disable" 1 "Enable" 2 "Error" 3 "N/A";
VAL_ 2164235073 EnableSplitPhase_command 0 "Normal - Three Phase Mode" 1 "Enable Split Phase Mode" 2 "Error" 3 "N/A";
VAL_ 2164235073 ForceRelayMX1_command 0 "Normal" 1 "Force On" 2 "Error" 3 "N/A";
VAL_ 2164235073 ForceRelayMX2_command 0 "Normal" 1 "Force On" 2 "Error" 3 "N/A";
VAL_ 2164235073 ForceRelayK1_Precharge_command 0 "Normal" 1 "Force On" 2 "Error" 3 "N/A";
VAL_ 2164235073 ForceRelayRelayK2_DCRun_comand 0 "Normal" 1 "Force On" 2 "Error" 3 "N/A";
VAL_ 2164235073 PhaseRotation_command 0 "Negative" 1 "Positive" 2 "Error" 3 "N/A";
VAL_ 2164235073 MasterFollowerMode_command 0 "Master" 1 "Follower" 2 "Error" 3 "N/A";
VAL_ 2365572087 State_status 0 "Power On Reset, and a quoted comma" 1 "Ready" 2 "Following" 3 "Fault" 4 "Forming" 5 "N/A" 6 "N/A" 7 "N/A" 8 "N/A" 9 "N/A" 10 "N/A" 11 "N/A" 12 "N/A" 13 "N/A" 14 "N/A" 15 "N/A";
VAL_ 2365572087 MX2Permissive_status 0 "Open" 1 "Closed" 2 "Error" 3 "N/A";
VAL_ 2365572087 PowerAvailAC_status 0 "None" 1 "Available" 2 "Error" 3 "N/A";
VAL_ 2365572087 PowerAvailDC_status 0 "None" 1 "Available" 2 "Error" 3 "N/A";
VAL_ 2365572087 PowerCircuitEnabled_status 0 "Disabled" 1 "Enabled" 2 "Error" 3 "N/A";
VAL_ 2365572087 HardwareEnable_status 0 "Not Active" 1 "Active" 2 "Error" 3 "N/A";
VAL_ 2365572087 Enable_echo 0 "Disable" 1 "Enable" 2 "Error" 3 "N/A";
VAL_ 2365572087 FaultClr_echo 0 "Normal" 1 "Clear Faults" 2 "Error" 3 "N/A";
VAL_ 2365572087 MessageValidModeControl_status 0 "Invalid" 1 "Valid" 2 "Error" 3 "N/A";
VAL_ 2365572087 MX1Permissive_status 0 "Open" 1 "Closed" 2 "Error" 3 "N/A";
VAL_ 2365572087 K2DCRunPermissive_status 0 "Open" 1 "Closed" 2 "Error" 3 "N/A";
VAL_ 2365572087 K1PrechargePermissive_status 0 "Open" 1 "Closed" 2 "Error" 3 "N/A";
VAL_ 2365572087 MessageValidPowerCMD_status 0 "Invalid" 1 "Valid" 2 "Error" 3 "N/A";
VAL_ 2365572087 MessageValidVF_status 0 "Invalid" 1 "Valid" 2 "Error" 3 "N/A";
VAL_ 2365572087 CANbus_status 0 "Normal" 1 "Warning" 3 "ErrorPassive" 4 "N/A";
VAL_ 2365572087 EnableUPSMode_echo 0 "Disable" 1 "Enable" 2 "Error" 3 "N/A";
VAL_ 2365572087 EnableSplitPhase_echo 0 "Normal - Three Phase Mode" 1 "Enable Split Phase Mode" 2 "Error" 3 "N/A";
VAL_ 2365572087 PhaseRotation_status 0 "Negative" 1 "Positive" 2 "Error" 3 "N/A";
VAL_ 2365572087 LineVoltageDetected_status 0 "No_Voltage" 1 "Voltage_Detected" 2 "Error" 3 "N/A";
VAL_ 2365572087 PhaseRotation_echo 0 "Negative" 1 "Positive" 2 "Error" 3 "N/A";
VAL_ 2365573367 BridgeAVoltageOk_status 0 "Normal" 1 "Fault Active" 2 "Error" 3 "N/A";
VAL_ 2365573367 OvercurrentAC_status 0 "Normal" 1 "Fault Active" 2 "Error" 3 "N/A";
VAL_ 2365573367 BridgeBVoltageOk_status 0 "Normal" 1 "Fault Active" 2 "Error" 3 "N/A";
VAL_ 2365573367 OvervoltageDC_status 0 "Normal" 1 "Fault Active" 2 "Error" 3 "N/A";
VAL_ 2365573367 OvertempPowerDevice_status 0 "Normal" 1 "Fault Active" 2 "Error" 3 "N/A";
VAL_ 2365573367 OvertempInternal_status 0 "Normal" 1 "Fault Active" 2 "Error" 3 "N/A";
VAL_ 2365573367 LossValidControlMessage_status 0 "Normal" 1 "Fault Active" 2 "Error" 3 "N/A";
VAL_ 2365573367 UndervoltageDC_status 0 "Normal" 1 "Fault Active" 2 "Error" 3 "N/A";
VAL_ 2365573367 ControlHardwareFail_status 0 "Normal" 1 "Fault Active" 2 "Error" 3 "N/A";
VAL_ 2365573367 OvercurrentDC_status 0 "Normal" 1 "Fault Active" 2 "Error" 3 "N/A";
VAL_ 2365573367 GeneralFault_status 0 "Normal" 1 "Fault Active" 2 "Error" 3 "N/A";
VAL_ 2365573367 LossOfAC_status 0 "Normal" 1 "Fault Active" 2 "Error" 3 "N/A";
VAL_ 2365573367 EStopShutdown_status 0 "Normal" 1 "Fault Active" 2 "Error" 3 "N/A";
VAL_ 2365573367 BridgeAFault_status 0 "Normal" 1 "FLT_A" 2 "N/A" 3 "FLT_C" 4 "OverVoltage" 5 "FLT_B" 6 "Overcurrent" 7 "5V";
VAL_ 2365573367 BridgeBFault_status 0 "Normal" 1 "FLT_A" 2 "N/A" 3 "FLT_C" 4 "OverVoltage" 5 "FLT_B" 6 "Overcurrent" 7 "5V";
VAL_ 2365573367 IllegalTransition_status 0 "Normal" 1 "Fault Active" 2 "Error" 3 "N/A";
VAL_ 2365573367 InvalidEEHeader_status 0 "Normal" 1 "Fault Active" 2 "Error" 3 "N/A";
VAL_ 2365573367 InvalidEESection_status 0 "Normal" 1 "Fault Active" 2 "Error" 3 "N/A";
VAL_ 2365573367 ThermalOverload 0 "Warning" 1 "Fault" 2 "Error" 3 "N/A";
VAL_ 2634000887 StatusNVParam_MUX 0 "ActParam0" 1 "ActLVM_ClearingTimes1" 2 "ActLVM_ClearingTimes2" 3 "ActLFM_Limits" 4 "ActLFM_ClearingTimes" 5 "StatusJ1939_Interface" 6 "StatusFault_Config" 7 "StatusContactorDelays1" 8 "StatusContactorDelays2" 9 "StatusContactorDelays3";
VAL_ 2634000887 StatusBaudrate 0 "125K" 1 "250K" 2 "500K" 3 "1M";
VAL_ 2634000887 StatusThermalOverload 0 "Warning" 1 "Fault" 2 "Error" 3 "N/A";
